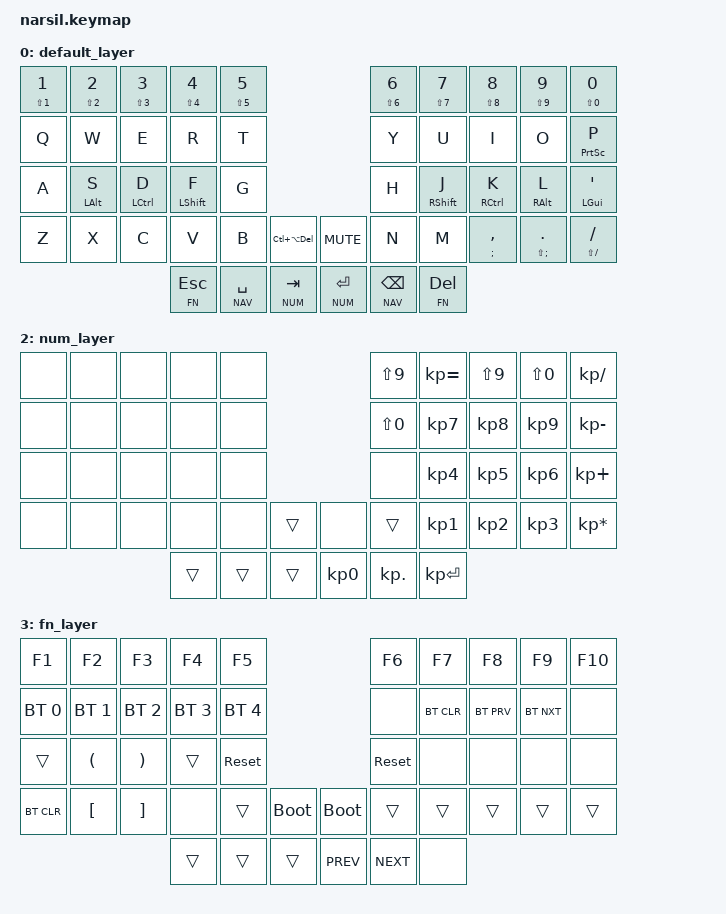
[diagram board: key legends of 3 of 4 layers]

  /*
  * Copyright (c) 2020 The ZMK Contributors
  *
  * SPDX-License-Identifier: MIT
  *
  */

  #include <behaviors.dtsi>
  #include <dt-bindings/zmk/keys.h>
  #include <dt-bindings/zmk/bt.h>
  #include <dt-bindings/zmk/ext_power.h>
  // #include <dt-bindings/zmk/dynamic-macros.h>


  #define DEFAULT 0
  #define NAV     1
  #define FN      2
  #define NUM     3

&mt {
    quick-tap-ms = <100>;
    global-quick-tap;
    flavor = "tap-preferred";
    tapping-term-ms = <180>;
};



/ {
    behaviors {
        pht: positional_hold_tap {
            compatible = "zmk,behavior-hold-tap";
            label = "POSITIONAL_HOLD_TAP";
            #binding-cells = <2>;
            flavor = "hold-preferred";
            tapping-term-ms = <400>;
            quick-tap-ms = <200>;
            bindings = <&kp>, <&kp>;
            hold-trigger-key-positions = <1>;    // <---[[the W key]]
        };
        gqt: global-quick-tap {
            compatible = "zmk,behavior-hold-tap";
            label = "GLOBAL_QUICK_TAP";
            #binding-cells = <2>;
            flavor = "tap-preferred";
            tapping-term-ms = <200>;
            quick-tap-ms = <125>;
            global-quick-tap;
            bindings = <&kp>, <&kp>;
        };
    };
};
  &sk {
    release-after-ms = <2000>;
    quick-release;
    /delete-property/ ignore-modifiers;
  };
/ {
    combos {
        compatible = "zmk,combos";

        combo_capslock {
            bindings = <&caps_word>;
            key-positions = <23 26>;
            layers = <0>;
        };
        combo_hyphen{
            bindings = <&kp MINUS>;
            key-positions = <8 9>;
            layers = <0>;
        };

        combo_equals{
            bindings = <&kp EQUAL>;
            key-positions = <18 19>;
            layers = <0>;
        };

        combo_backslash{
            bindings = <&kp BSLH>;
            key-positions = <38 39>;
            layers = <0>;
        };
        combo_lock{
            bindings = <&kp LG(L)>;
            key-positions = <29 39>;
            layers = <0>;
        };
    };
};
  / {
    keymap {
      compatible = "zmk,keymap";
        default_layer {
// -------------------------------------------------------------------------------------------------
// | 1     | 2    | 3    | 4   | 5   |                               | 6   | 7   | 8   | 9   | 0   |
// | Q     | W    | E    | R   | T   |                               | Y   | U   | I   | O   | P   |
// | A     | S    | D    | F   | G   |                               | H   | J   | K   | L   | ;   |
// | Z     | X    | C    | V   | B   |  C/A/D  |            |  MUTE  | N   | M   | ,   | .   | /   |
//                     | FN/ESC|NAV/SPACE|NUM/TAB|      |NUM/ENTER|NAV/BSPACE|FN/DEL |
          bindings = <
    &gqt LS(N1) N1 &gqt LS(N2) N2 &gqt LS(N3) N3 &gqt LS(N4) N4 &gqt LS(N5) N5       &gqt LS(N6) N6 &gqt LS(N7) N7 &gqt LS(N8) N8 &gqt LS(N9) N9 &gqt LS(N0) N0 
    &kp Q     &kp W     &kp E         &kp R        &kp T                                   &kp Y      &kp U          &kp I           &kp O        &gqt PSCRN P   
    &kp A  &mt LALT S  &mt LCTRL D  &mt LSHFT F    &kp G                                   &kp H    &mt RSHFT J  &mt RCTRL K      &mt RALT L      &mt LGUI SQT 
    &kp Z     &kp X     &kp C         &kp V        &kp B  &kp LC(LA(DEL))       &kp C_MUTE &kp N      &kp M      &gqt SEMI COMMA &gqt LS(SEMI) DOT &gqt LS(FSLH) FSLH 
                                    &lt FN ESC     &lt NAV SPACE  &lt NUM TAB   &lt NUM RET      &lt NAV BSPC    &lt FN DEL   
          >;
          sensor-bindings = <&inc_dec_kp C_VOL_DN C_VOL_UP &inc_dec_kp DOWN UP>;
        };

        nav_layer {
// -------------------------------------------------------------------------------------------------
// | none  | none  | none  | none  | none |                  | none  | HOME | INS  | PG_UP | none  | 
// | none  | none  | none  | none  | none |                  | none  | END  | UP   | PG_DN | none  | 
// | none  | none  | none  | none  | none |                  | PSCRN | LEFT | DOWN | RIGHT | none  | 
// | none  | none  | none  | none  | none | trans |  | trans | none  | none | none | none  | none  | 
//                         | trans | trans| trans |  | trans | trans | trans|      
          bindings = <
    &none  &none  &none  &none  &none                   &none     &kp HOME   &kp INS  &kp PG_UP &none  
    &none  &none  &none  &none  &none                   &none     &kp END    &kp UP   &kp PG_DN &none  
    &none  &none  &none  &none  &none                   &kp PSCRN &kp LEFT   &kp DOWN &kp RIGHT 
    &none  &none  &none  &none  &none  &trans  &trans   &tog NUM  &trans     &none    &none     &none   
                         &trans &trans &trans  &trans   &trans    &trans
          >;

          sensor-bindings = <&inc_dec_kp UP DOWN &inc_dec_kp C_VOL_DN C_VOL_UP>;
        };

        num_layer {
// -------------------------------------------------------------------------------------------------
//  | none | none  | none  | none  | none |                  | (     | 	 =     | (   |   ) | /  | 
//  | none | none  | none  | none  | none |                  |     ) |    7    | 8   | 9   | -  | 
//  | none | none  | none  | none  | none |                  | none  |    4    | 5   | 6   | +  | 
//  | none | none  | none  | none  | none | trans |  | trans | none  |    1    | 2   | 3   | *  | 
//                         | trans | trans| trans |  |    0  | .     | ENTER   | 
          bindings = <
   &none &none  &none  &none  &none                       &kp LS(N9)  &kp KP_EQUAL &kp LS(N9)   &kp LS(N0) 	&kp KP_SLASH 
   &none &none  &none  &none  &none                       &kp LS(N0)  &kp KP_N7    &kp KP_N8    &kp KP_N9	&kp KP_MINUS 
   &none &none  &none  &none  &none                       &none       &kp KP_N4    &kp KP_N5    &kp KP_N6 	&kp KP_PLUS  
   &none &none  &none  &none  &none &trans         &none  &trans      &kp KP_N1    &kp KP_N2    &kp KP_N3	&kp KP_ASTERISK   
                       &trans &trans &trans    &kp KP_N0  &kp KP_DOT  &kp KP_ENTER      
          >;

          sensor-bindings = <&inc_dec_kp LEFT RIGHT &inc_dec_kp DOWN UP>;
        };

        fn_layer {
// ---------------------------------------------------------------------------------------------------------------------
// | F1     | F2      | F3      | F4      | F5       |                      | F6    | F7     | F8     | F9      | F10  |
// |BT_SEL 0| BT_SEL 1| BT_SEL 2| BT_SEL 3| BT_SEL 4 |                      | none  | BT_CLR | BT_PRV | BT_NXT  | none |
// | OUT_TOG|    (    |    )    | none    | reset    |                      | reset | none   | none   | none    | none |
// |BT_CLR  |    [    |    ]    | none    | trans    |bootloader||bootloader| none  | none   | none   | none    | MacroCORD |
//                              | trans   | trans    |   trans  ||  trans   | trans | trans  | 
          bindings = <
    &kp F1       &kp F2        &kp F3      &kp F4       &kp F5                                  &kp F6      &kp F7      &kp F8     &kp F9     &kp F10 
    &bt BT_SEL 0 &bt BT_SEL 1 &bt BT_SEL 2 &bt BT_SEL 3 &bt BT_SEL 4                            &none       &bt BT_CLR  &bt BT_PRV &bt BT_NXT &none   
    &trans 	 &kp LPAR     &kp RPAR     &trans 	&sys_reset                                      &sys_reset  &none       &none      &none      &none
    &bt BT_CLR   &kp LBKT     &kp RBKT     &none        &trans  &bootloader   &bootloader       &trans      &trans      &trans     &trans     &trans  // &dyn RECORD 
                                           &trans       &trans  &trans        &kp C_PREV        &kp C_NEXT  &none
          >;

          sensor-bindings = <&inc_dec_kp LEFT RIGHT &inc_dec_kp DOWN UP>;
        };
    };
  };
